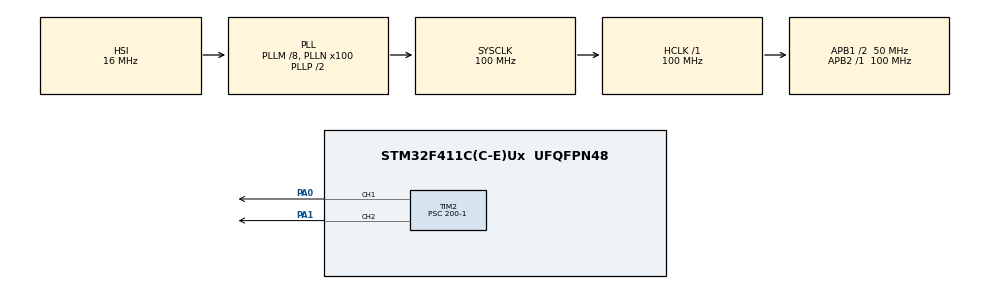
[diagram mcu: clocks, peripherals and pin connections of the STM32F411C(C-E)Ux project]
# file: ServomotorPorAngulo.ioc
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Mcu.Family=STM32F4
Mcu.Name=STM32F411C(C-E)Ux
Mcu.Package=UFQFPN48
NVIC.PriorityGroup=NVIC_PRIORITYGROUP_4
PA0-WKUP.Signal=S_TIM2_CH1_ETR
PA1.Signal=S_TIM2_CH2
PA13.Mode=Serial_Wire
PA13.Signal=SYS_JTMS-SWDIO
PA14.Mode=Serial_Wire
PA14.Signal=SYS_JTCK-SWCLK
PH0\ -\ OSC_IN.Mode=HSE-External-Oscillator
PH0\ -\ OSC_IN.Signal=RCC_OSC_IN
PH1\ -\ OSC_OUT.Mode=HSE-External-Oscillator
PH1\ -\ OSC_OUT.Signal=RCC_OSC_OUT
ProjectManager.HeapSize=0x200
ProjectManager.StackSize=0x400
ProjectManager.TargetToolchain=STM32CubeIDE
RCC.48MHZClocksFreq_Value=50000000
RCC.AHBFreq_Value=100000000
RCC.APB1CLKDivider=RCC_HCLK_DIV2
RCC.APB1Freq_Value=50000000
RCC.APB1TimFreq_Value=100000000
RCC.APB2Freq_Value=100000000
RCC.APB2TimFreq_Value=100000000
RCC.CortexFreq_Value=100000000
RCC.HCLKFreq_Value=100000000
RCC.HSE_VALUE=25000000
RCC.HSI_VALUE=16000000
RCC.LSE_VALUE=32768
RCC.PLLM=8
RCC.PLLN=100
RCC.SYSCLKFreq_VALUE=100000000
RCC.SYSCLKSource=RCC_SYSCLKSOURCE_PLLCLK
RCC.VCOOutputFreq_Value=200000000
SH.S_TIM2_CH1_ETR.0=TIM2_CH1,PWM Generation1 CH1
SH.S_TIM2_CH2.0=TIM2_CH2,PWM Generation2 CH2
TIM2.Channel-PWM\ Generation1\ CH1=TIM_CHANNEL_1
TIM2.Channel-PWM\ Generation2\ CH2=TIM_CHANNEL_2
TIM2.Period=10000-1
TIM2.Prescaler=200-1
VP_TIM2_VS_ClockSourceINT.Mode=Internal
board=custom

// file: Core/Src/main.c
/* USER CODE BEGIN Header */
/**
  ******************************************************************************
  * @file           : main.c
  * @brief          : Main program body
  ******************************************************************************
  * @attention
  *
  * Copyright (c) 2025 STMicroelectronics.
  * All rights reserved.
  *
  * This software is licensed under terms that can be found in the LICENSE file
  * in the root directory of this software component.
  * If no LICENSE file comes with this software, it is provided AS-IS.
  *
  ******************************************************************************
  */
/* USER CODE END Header */
#include "main.h"

TIM_HandleTypeDef htim2;

void SystemClock_Config(void);
static void MX_GPIO_Init(void);
static void MX_TIM2_Init(void);
/* USER CODE BEGIN PFP */

/**
 * @brief Configura el ángulo de un servomotor mediante PWM.
 * @param htim Puntero al manejador del Timer utilizado.
 * @param channel Canal del Timer donde está conectado el servomotor.
 * @param angle Ángulo deseado (0 a 180 grados).
 *
 * La función calcula la duración del pulso en función del ángulo deseado y
 * ajusta la señal PWM en el canal correspondiente.
 */
void set_servo_angle(TIM_HandleTypeDef *htim, uint32_t channel, uint8_t angle);

/* USER CODE END PFP */

int main(void)
{

  /* MCU Configuration--------------------------------------------------------*/

  /* Reset of all peripherals, Initializes the Flash interface and the Systick. */
  HAL_Init();

  /* Configure the system clock */
  SystemClock_Config();

  /* Initialize all configured peripherals */
  MX_GPIO_Init();
  MX_TIM2_Init();
  /* USER CODE BEGIN 2 */
  HAL_TIM_PWM_Start(&htim2, TIM_CHANNEL_1); ///< Inicia PWM en el canal 1 del Timer 2.
  HAL_TIM_PWM_Start(&htim2, TIM_CHANNEL_2); ///< Inicia PWM en el canal 2 del Timer 2.
  /* USER CODE END 2 */

  /* Infinite loop */
  /* USER CODE BEGIN WHILE */
  while (1)
  {
      // Posicionar el primer servomotor en 0° y el segundo en 180°
      set_servo_angle(&htim2, TIM_CHANNEL_1, 0);
      set_servo_angle(&htim2, TIM_CHANNEL_2, 180);
      HAL_Delay(1000);

      // Posicionar ambos servomotores en 90°
      set_servo_angle(&htim2, TIM_CHANNEL_1, 90);
      set_servo_angle(&htim2, TIM_CHANNEL_2, 90);
      HAL_Delay(1000);

      // Posicionar el primer servomotor en 180° y el segundo en 0°
      set_servo_angle(&htim2, TIM_CHANNEL_1, 180);
      set_servo_angle(&htim2, TIM_CHANNEL_2, 0);
      HAL_Delay(1000);
    /* USER CODE END WHILE */

  }
}

void SystemClock_Config(void)
{
  RCC_OscInitTypeDef RCC_OscInitStruct = {0};
  RCC_ClkInitTypeDef RCC_ClkInitStruct = {0};

  /** Configure the main internal regulator output voltage
  */
  __HAL_RCC_PWR_CLK_ENABLE();
  __HAL_PWR_VOLTAGESCALING_CONFIG(PWR_REGULATOR_VOLTAGE_SCALE1);

  /** Initializes the RCC Oscillators according to the specified parameters
  * in the RCC_OscInitTypeDef structure.
  */
  RCC_OscInitStruct.OscillatorType = RCC_OSCILLATORTYPE_HSI;
  RCC_OscInitStruct.HSIState = RCC_HSI_ON;
  RCC_OscInitStruct.HSICalibrationValue = RCC_HSICALIBRATION_DEFAULT;
  RCC_OscInitStruct.PLL.PLLState = RCC_PLL_ON;
  RCC_OscInitStruct.PLL.PLLSource = RCC_PLLSOURCE_HSI;
  RCC_OscInitStruct.PLL.PLLM = 8;
  RCC_OscInitStruct.PLL.PLLN = 100;
  RCC_OscInitStruct.PLL.PLLP = RCC_PLLP_DIV2;
  RCC_OscInitStruct.PLL.PLLQ = 4;
  if (HAL_RCC_OscConfig(&RCC_OscInitStruct) != HAL_OK)
  {
    Error_Handler();
  }

  /** Initializes the CPU, AHB and APB buses clocks
  */
  RCC_ClkInitStruct.ClockType = RCC_CLOCKTYPE_HCLK|RCC_CLOCKTYPE_SYSCLK
                              |RCC_CLOCKTYPE_PCLK1|RCC_CLOCKTYPE_PCLK2;
  RCC_ClkInitStruct.SYSCLKSource = RCC_SYSCLKSOURCE_PLLCLK;
  RCC_ClkInitStruct.AHBCLKDivider = RCC_SYSCLK_DIV1;
  RCC_ClkInitStruct.APB1CLKDivider = RCC_HCLK_DIV2;
  RCC_ClkInitStruct.APB2CLKDivider = RCC_HCLK_DIV1;

  if (HAL_RCC_ClockConfig(&RCC_ClkInitStruct, FLASH_LATENCY_3) != HAL_OK)
  {
    Error_Handler();
  }
}

static void MX_TIM2_Init(void)
{

  TIM_ClockConfigTypeDef sClockSourceConfig = {0};
  TIM_MasterConfigTypeDef sMasterConfig = {0};
  TIM_OC_InitTypeDef sConfigOC = {0};

  htim2.Instance = TIM2;
  htim2.Init.Prescaler = 200-1;
  htim2.Init.CounterMode = TIM_COUNTERMODE_UP;
  htim2.Init.Period = 10000-1;
  htim2.Init.ClockDivision = TIM_CLOCKDIVISION_DIV1;
  htim2.Init.AutoReloadPreload = TIM_AUTORELOAD_PRELOAD_DISABLE;
  if (HAL_TIM_Base_Init(&htim2) != HAL_OK)
  {
    Error_Handler();
  }
  sClockSourceConfig.ClockSource = TIM_CLOCKSOURCE_INTERNAL;
  if (HAL_TIM_ConfigClockSource(&htim2, &sClockSourceConfig) != HAL_OK)
  {
    Error_Handler();
  }
  if (HAL_TIM_PWM_Init(&htim2) != HAL_OK)
  {
    Error_Handler();
  }
  sMasterConfig.MasterOutputTrigger = TIM_TRGO_RESET;
  sMasterConfig.MasterSlaveMode = TIM_MASTERSLAVEMODE_DISABLE;
  if (HAL_TIMEx_MasterConfigSynchronization(&htim2, &sMasterConfig) != HAL_OK)
  {
    Error_Handler();
  }
  sConfigOC.OCMode = TIM_OCMODE_PWM1;
  sConfigOC.Pulse = 0;
  sConfigOC.OCPolarity = TIM_OCPOLARITY_HIGH;
  sConfigOC.OCFastMode = TIM_OCFAST_DISABLE;
  if (HAL_TIM_PWM_ConfigChannel(&htim2, &sConfigOC, TIM_CHANNEL_1) != HAL_OK)
  {
    Error_Handler();
  }
  if (HAL_TIM_PWM_ConfigChannel(&htim2, &sConfigOC, TIM_CHANNEL_2) != HAL_OK)
  {
    Error_Handler();
  }
  HAL_TIM_MspPostInit(&htim2);

}

static void MX_GPIO_Init(void)
{

  /* GPIO Ports Clock Enable */
  __HAL_RCC_GPIOH_CLK_ENABLE();
  __HAL_RCC_GPIOA_CLK_ENABLE();

}

/* USER CODE BEGIN 4 */

/**
 * @brief Ajusta el ángulo del servomotor generando una señal PWM.
 * @param htim Puntero al manejador del Timer.
 * @param channel Canal del Timer donde está conectado el servomotor.
 * @param angle Ángulo deseado (0 a 180 grados).
 *
 * La conversión de ángulo a pulso PWM se realiza mediante la ecuación:
 *    pulse = 5.56 * angle + 250;
 * donde 5.56 es la relación entre el ángulo y el ancho de pulso en microsegundos,
 * y 250 es el pulso mínimo correspondiente a 0°.
 */
void set_servo_angle(TIM_HandleTypeDef *htim, uint32_t channel, uint8_t angle)
{
    // 1. Calcular la duración del pulso en función del ángulo
    uint16_t pulse = (uint16_t)(5.56 * angle + 250);

    // 2. Establecer la comparación del Timer en el canal especificado
    __HAL_TIM_SET_COMPARE(htim, channel, pulse);
}

/* USER CODE END 4 */

void Error_Handler(void)
{
  __disable_irq();
  while (1)
  {
  }
}
